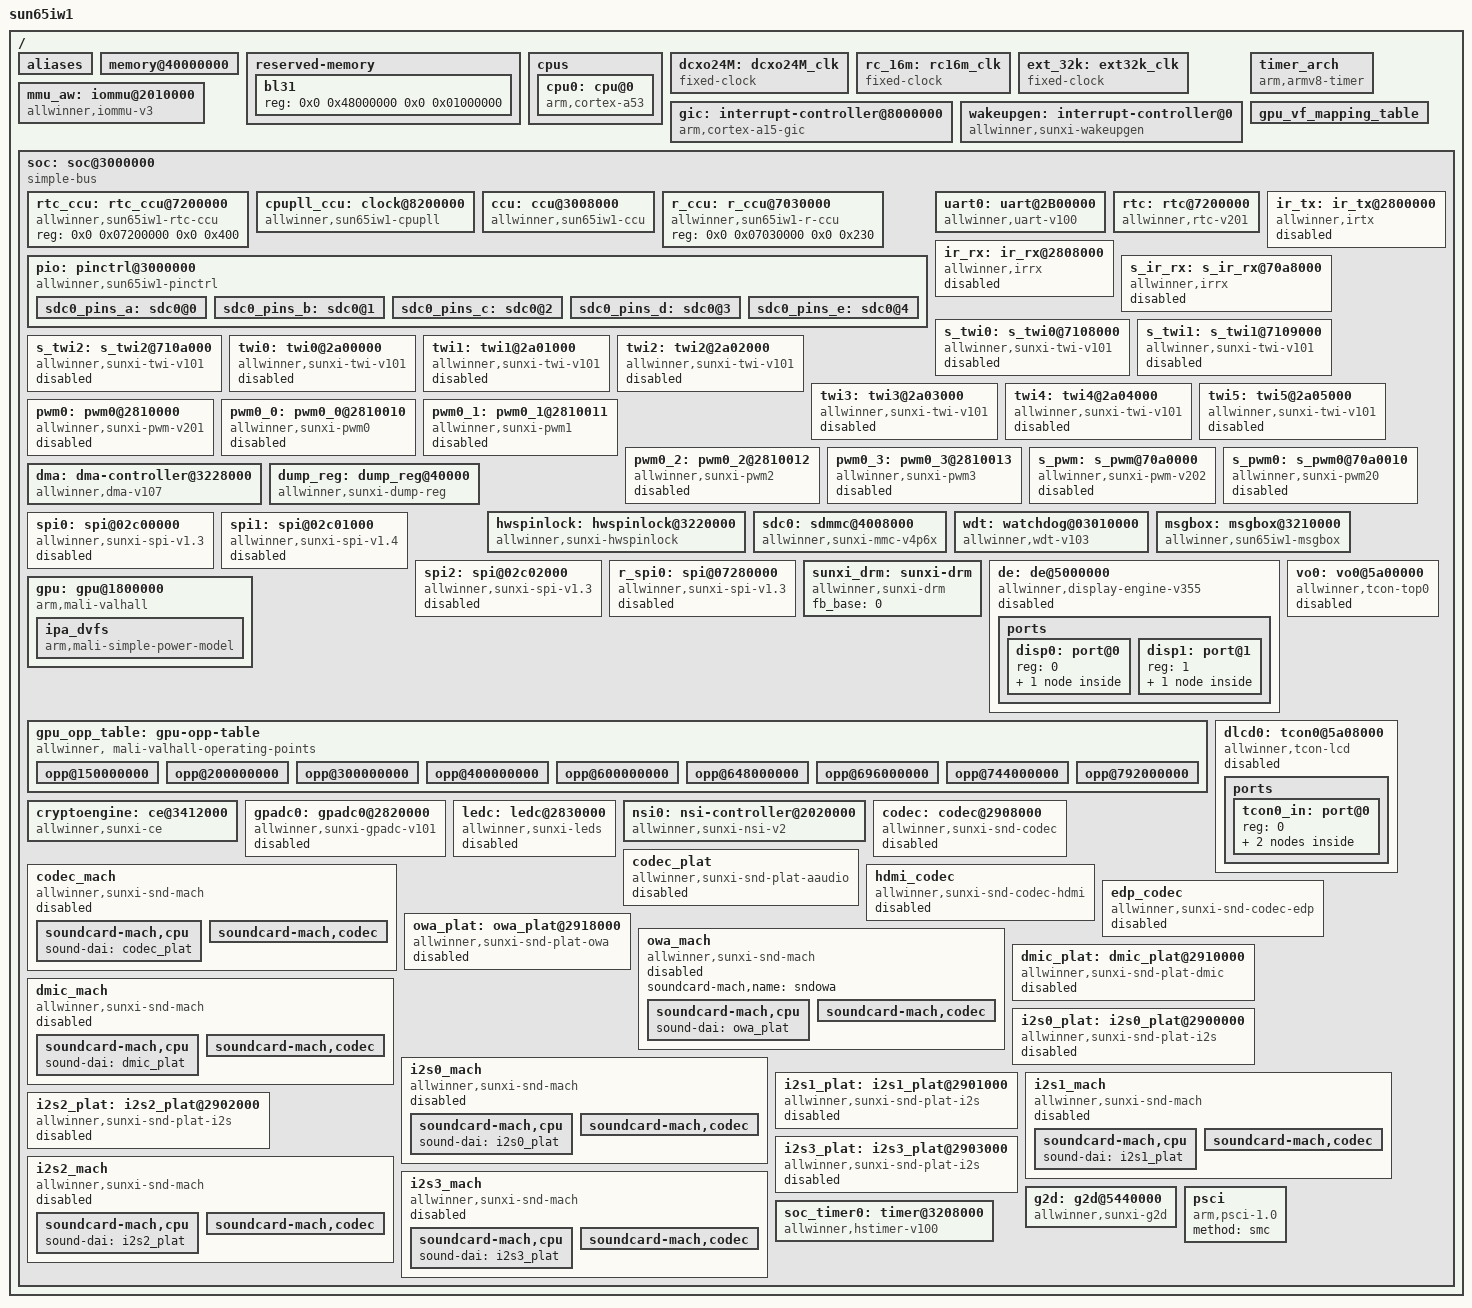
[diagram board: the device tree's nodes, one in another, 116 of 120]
// SPDX-License-Identifier: (GPL-2.0+ or MIT)
#include <dt-bindings/clock/sun65iw1-ccu.h>
#include <dt-bindings/clock/sun65iw1-rtc.h>
#include <dt-bindings/clock/sun65iw1-r-ccu.h>
#include <dt-bindings/clock/sun65iw1-displl-ccu.h>
#include <dt-bindings/gpio/gpio.h>
#include <dt-bindings/gpio/sun4i-gpio.h>
#include <dt-bindings/reset/sun65iw1-ccu.h>
#include <dt-bindings/reset/sun65iw1-r-ccu.h>
#include <dt-bindings/interrupt-controller/arm-gic.h>
#include <dt-bindings/phy/phy.h>
#include <dt-bindings/thermal/thermal.h>
#include <dt-bindings/spi/sunxi-spi.h>

/ {
	model = "sun65iw1";
	interrupt-parent = <&wakeupgen>;
	#address-cells = <2>;
	#size-cells = <2>;

	aliases {
		serial0 = &uart0;
		ir0 = &ir_rx;
		ir1 = &s_ir_rx;
		spi0 = &spi0;
		spi1 = &spi1;
		spi2 = &spi2;
		spi3 = &r_spi0;
		twi0 = &twi0;
		twi1 = &twi1;
		twi2 = &twi2;
		twi3 = &twi3;
		twi4 = &twi4;
		twi5 = &twi5;
		twi6 = &s_twi0;
		twi7 = &s_twi1;
		twi8 = &s_twi2;
	};

	/* avoid panic when memory-node err(from uboot) */
	memory@40000000 {
		device_type = "memory";
		reg = <0x00000000 0x40000000 0x00000000 0x20000000>;
	};

	reserved-memory {
		#address-cells = <2>;
		#size-cells = <2>;
		ranges;

		bl31 {
			reg = <0x0 0x48000000 0x0 0x01000000>;
		};
	};

	cpus {
		#address-cells = <2>;
		#size-cells = <0>;

		cpu0: cpu@0 {
			device_type = "cpu";
			compatible = "arm,cortex-a53";
			reg = <0x0 0x0>;
			enable-method = "psci";
		};
	};

	dcxo24M: dcxo24M_clk {
		#clock-cells = <0>;
		compatible = "fixed-clock";
		clock-frequency = <24000000>;
		clock-output-names = "dcxo24M";
	};

	rc_16m: rc16m_clk {
		#clock-cells = <0>;
		compatible = "fixed-clock";
		clock-frequency = <16000000>;
		clock-accuracy = <300000000>;
		clock-output-names = "rc-16m";
	};

	ext_32k: ext32k_clk {
		#clock-cells = <0>;
		compatible = "fixed-clock";
		clock-frequency = <32768>;
		clock-output-names = "ext-32k";
	};

	gic: interrupt-controller@8000000{
		compatible = "arm,cortex-a15-gic", "arm,cortex-a9-gic";
		#interrupt-cells = <3>;
		#address-cells = <0>;
		device_type = "gic";
		interrupt-controller;
		reg = <0x0 0x08001000 0 0x1000>, /* GIC Dist */
			<0x0 0x08002000 0 0x2000>, /* GIC CPU */
			<0x0 0x08004000 0 0x2000>, /* GIC VCPU Control */
			<0x0 0x08006000 0 0x2000>; /* GIC VCPU */
		interrupts = <GIC_PPI 9 0xf04>; /* GIC Maintenence IRQ */
		interrupt-parent = <&gic>;
	};

	wakeupgen: interrupt-controller@0 {
		compatible = "allwinner,sunxi-wakeupgen";
		interrupt-controller;
		#interrupt-cells = <3>;
		#address-cells = <0>;
		interrupt-parent = <&gic>;
	};

	timer_arch {
		compatible = "arm,armv8-timer";
		interrupts = <GIC_PPI 13 (GIC_CPU_MASK_SIMPLE(4) | IRQ_TYPE_LEVEL_LOW)>,
			     <GIC_PPI 14 (GIC_CPU_MASK_SIMPLE(4) | IRQ_TYPE_LEVEL_LOW)>,
			     <GIC_PPI 11 (GIC_CPU_MASK_SIMPLE(4) | IRQ_TYPE_LEVEL_LOW)>,
			     <GIC_PPI 10 (GIC_CPU_MASK_SIMPLE(4) | IRQ_TYPE_LEVEL_LOW)>;
		clock-frequency = <24000000>;
		interrupt-parent = <&gic>;
		arm,no-tick-in-suspend;
	};

	mmu_aw: iommu@2010000 {
		compatible = "allwinner,iommu-v3";
		reg = <0x0 0x02000000 0x0 0x1000>;
		interrupts = <GIC_SPI 91 IRQ_TYPE_LEVEL_HIGH>;
		interrupt-names = "iommu-irq";
		clocks = <&ccu CLK_APB_IOMMU>;
		clock-names = "iommu";
		/* clock-frequency = <24000000>; */
		#iommu-cells = <2>;
		version=<0x17>;
		tlb_prefetch = <0x3007f>;
		tlb_invalid_mode = <0x1>;
		ptw_invalid_mode = <0x1>;
		masters = "ISP", "CSI", "VE0", "Eink", "G2D",
			"DE", "RESERVED", "DEBUG_MODE";
		valid_masters=<7>;
	};

	gpu_vf_mapping_table: gpu_vf_mapping_table {
		table = <
			0x01 1
			0x02 2
			0x12 21
			0x04 3
			0x14 31
			0x05 4
			0x06 5
			>;
	};

	soc: soc@3000000 {
		compatible = "simple-bus";
		#address-cells = <2>;
		#size-cells = <2>;
		ranges;

		rtc_ccu: rtc_ccu@7200000 {
			compatible = "allwinner,sun65iw1-rtc-ccu";
			reg = <0x0 0x07200000 0x0 0x400>;
			#clock-cells = <1>;
			#reset-cells = <1>;
		};

		cpupll_ccu: clock@8200000 {
			compatible = "allwinner,sun65iw1-cpupll";
			reg = <0x0 0x08200000 0x0 0x050c>;
			#clock-cells = <1>;
			#reset-cells = <1>;
			pll_step = <0x9>;
			/* pll_ssc will divid pll_ssc_scale in code
			 * keep value 0 < pll_ssc < 10
			 */
			pll_ssc_scale = <0xa>;
			pll_ssc = <0x1>;
		};

		ccu: ccu@3008000 {
			compatible = "allwinner,sun65iw1-ccu";
			reg = <0x0 0x03008000 0x0 0x2000>;
			clocks = <&dcxo24M>, <&rtc_ccu CLK_OSC32K>, <&rc_16m>;
			clock-names = "hosc", "losc", "iosc";
			#clock-cells = <1>;
			#reset-cells = <1>;
		};

		r_ccu: r_ccu@7030000 {
			compatible = "allwinner,sun65iw1-r-ccu";
			reg = <0x0 0x07030000 0x0 0x230>;
			#clock-cells = <1>;
			#reset-cells = <1>;
		};

		pio: pinctrl@3000000 {
			compatible = "allwinner,sun65iw1-pinctrl";
			reg = <0x0 0x03000000 0x0 0x800>;
			interrupts = <GIC_SPI 134 IRQ_TYPE_LEVEL_HIGH>,
				     <GIC_SPI 138 IRQ_TYPE_LEVEL_HIGH>;
			clocks = <&ccu CLK_APB1>, <&dcxo24M>, <&rtc_ccu CLK_OSC32K>;
			clock-names = "apb", "hosc", "losc";
			gpio-controller;
			#gpio-cells = <3>;
			interrupt-controller;
			#interrupt-cells = <3>;

			sdc0_pins_a: sdc0@0 {
				pins = "PF0", "PF1", "PF2",
						"PF3", "PF4", "PF5";
				function = "sdc0";
				drive-strength = <40>;
				bias-pull-up;
				power-source = <3300>;
			};

			sdc0_pins_b: sdc0@1 {
				pins = "PF0", "PF1", "PF2",
						"PF3", "PF4", "PF5";
				function = "sdc0";
				drive-strength = <40>;
				bias-pull-up;
				power-source = <1800>;
			};

			sdc0_pins_c: sdc0@2 {
				pins = "PF0", "PF1", "PF2",
				"PF3", "PF4", "PF5";
				function = "gpio_in";
			};

			/* TODO: add jtag pin */
			sdc0_pins_d: sdc0@3 {
				pins = "PF2", "PF4";
				function = "uart0";
				drive-strength = <10>;
				bias-pull-up;
			};

			sdc0_pins_e: sdc0@4 {
				pins = "PF0", "PF1", "PF3",
						"PF5";
				function = "jtag";
				drive-strength = <10>;
				bias-pull-up;
			};

		};

		uart0: uart@2B00000 {
			compatible = "allwinner,uart-v100";
			reg = <0x0 0x02B00000 0x0 0x400>;
			interrupts = <GIC_SPI 2 IRQ_TYPE_LEVEL_HIGH>;
			clocks = <&ccu CLK_BUS_UART0>;
			resets = <&ccu RST_BUS_UART0>;
			uart0_port = <0>;
			uart0_type = <2>;
		};

		rtc: rtc@7200000 {
			compatible = "allwinner,rtc-v201";
			device_type = "rtc";
			wakeup-source;
			reg = <0x0 0x07200000 0x0 0x320>;
			interrupts = <GIC_SPI 232 IRQ_TYPE_LEVEL_HIGH>;
			clocks = <&r_ccu CLK_RTC>, <&rtc_ccu CLK_RTC_1K>, <&rtc_ccu CLK_RTC_SPI>;
			clock-names = "r-ahb-rtc", "rtc-1k", "rtc-spi";
			resets = <&r_ccu RST_BUS_RTC>;
			gpr_cur_pos = <6>;
			gpr_bootcount_pos = <7>;
		};

		ir_tx: ir_tx@2800000 {
			compatible = "allwinner,irtx";
			reg = <0x0 0x02800000 0x0 0x400>;
			interrupts = <GIC_SPI 30 IRQ_TYPE_LEVEL_HIGH>;
			clocks = <&ccu CLK_APB_IRTX>, <&dcxo24M>, <&ccu CLK_IRTX>;
			clock-names = "bus", "pclk", "mclk";
			resets = <&ccu RST_BUS_IRTX>;
			status = "disabled";
		};

		ir_rx: ir_rx@2808000 {
			compatible = "allwinner,irrx";
			reg = <0x0 0x02808000 0x0 0x400>;
			interrupts = <GIC_SPI 31 IRQ_TYPE_LEVEL_HIGH>;
			clocks = <&ccu CLK_APB_IRRX0>, <&dcxo24M>, <&ccu CLK_IRRX0>;
			clock-names = "bus", "pclk", "mclk";
			resets = <&ccu RST_BUS_IRRX0>;
			status = "disabled";
		};

		s_ir_rx: s_ir_rx@70a8000 {
			compatible = "allwinner,irrx";
			reg = <0x0 0x070a8000 0x0 0x400>;
			interrupts = <GIC_SPI 242 IRQ_TYPE_LEVEL_HIGH>;
			clocks = <&r_ccu CLK_BUS_R_IRRX>, <&dcxo24M>, <&r_ccu CLK_R_IRRX>;
			clock-names = "bus", "pclk", "mclk";
			resets = <&r_ccu RST_BUS_R_IRRX>;
			status = "disabled";
		};

		s_twi0: s_twi0@7108000 {
			#address-cells = <1>;
			#size-cells = <0>;
			compatible = "allwinner,sunxi-twi-v101";
			device_type = "s_twi0";
			reg = <0x0 0x07108000 0x0 0x400>;
			interrupts = <GIC_SPI 239 IRQ_TYPE_LEVEL_HIGH>;
			clocks = <&r_ccu CLK_R_TWI0>;
			clock-names = "bus";
			resets = <&r_ccu RST_BUS_R_TWI0>;
			dmas = <&dma 56>, <&dma 56>;
			dma-names = "tx", "rx";
			status = "disabled";
		};

		s_twi1: s_twi1@7109000 {
			#address-cells = <1>;
			#size-cells = <0>;
			compatible = "allwinner,sunxi-twi-v101";
			device_type = "s_twi1";
			reg = <0x0 0x07109000 0x0 0x400>;
			interrupts = <GIC_SPI 240 IRQ_TYPE_LEVEL_HIGH>;
			clocks = <&r_ccu CLK_R_TWI1>;
			clock-names = "bus";
			resets = <&r_ccu RST_BUS_R_TWI1>;
			dmas = <&dma 57>, <&dma 57>;
			dma-names = "tx", "rx";
			status = "disabled";
		};

		s_twi2: s_twi2@710a000 {
			#address-cells = <1>;
			#size-cells = <0>;
			compatible = "allwinner,sunxi-twi-v101";
			device_type = "s_twi2";
			reg = <0x0 0x0710a000 0x0 0x400>;
			interrupts = <GIC_SPI 241 IRQ_TYPE_LEVEL_HIGH>;
			clocks = <&r_ccu CLK_R_TWI2>;
			clock-names = "bus";
			resets = <&r_ccu RST_BUS_R_TWI2>;
			dmas = <&dma 58>, <&dma 58>;
			dma-names = "tx", "rx";
			status = "disabled";
		};

		twi0: twi0@2a00000 {
			#address-cells = <1>;
			#size-cells = <0>;
			compatible = "allwinner,sunxi-twi-v101";
			device_type = "twi0";
			reg = <0x0 0x02a00000 0x0 0x400>;
			interrupts = <GIC_SPI 10 IRQ_TYPE_LEVEL_HIGH>;
			clocks = <&ccu CLK_BUS_TWI0>;
			clock-names = "bus";
			resets = <&ccu RST_BUS_TWI0>;
			dmas = <&dma 14>, <&dma 14>;
			dma-names = "tx", "rx";
			status = "disabled";
		};

		twi1: twi1@2a01000 {
			#address-cells = <1>;
			#size-cells = <0>;
			compatible = "allwinner,sunxi-twi-v101";
			device_type = "twi1";
			reg = <0x0 0x02a01000 0x0 0x400>;
			interrupts = <GIC_SPI 11 IRQ_TYPE_LEVEL_HIGH>;
			clocks = <&ccu CLK_BUS_TWI1>;
			clock-names = "bus";
			resets = <&ccu RST_BUS_TWI1>;
			dmas = <&dma 15>, <&dma 15>;
			dma-names = "tx", "rx";
			status = "disabled";
		};

		twi2: twi2@2a02000 {
			#address-cells = <1>;
			#size-cells = <0>;
			compatible = "allwinner,sunxi-twi-v101";
			device_type = "twi2";
			reg = <0x0 0x02a02000 0x0 0x400>;
			interrupts = <GIC_SPI 12 IRQ_TYPE_LEVEL_HIGH>;
			clocks = <&ccu CLK_BUS_TWI2>;
			clock-names = "bus";
			resets = <&ccu RST_BUS_TWI2>;
			dmas = <&dma 16>, <&dma 16>;
			dma-names = "tx", "rx";
			status = "disabled";
		};

		twi3: twi3@2a03000 {
			#address-cells = <1>;
			#size-cells = <0>;
			compatible = "allwinner,sunxi-twi-v101";
			device_type = "twi3";
			reg = <0x0 0x02a03000 0x0 0x400>;
			interrupts = <GIC_SPI 13 IRQ_TYPE_LEVEL_HIGH>;
			clocks = <&ccu CLK_BUS_TWI3>;
			clock-names = "bus";
			resets = <&ccu RST_BUS_TWI3>;
			dmas = <&dma 17>, <&dma 17>;
			dma-names = "tx", "rx";
			status = "disabled";
		};

		twi4: twi4@2a04000 {
			#address-cells = <1>;
			#size-cells = <0>;
			compatible = "allwinner,sunxi-twi-v101";
			device_type = "twi4";
			reg = <0x0 0x02a04000 0x0 0x400>;
			interrupts = <GIC_SPI 14 IRQ_TYPE_LEVEL_HIGH>;
			clocks = <&ccu CLK_BUS_TWI4>;
			clock-names = "bus";
			resets = <&ccu RST_BUS_TWI4>;
			dmas = <&dma 18>, <&dma 18>;
			dma-names = "tx", "rx";
			status = "disabled";
		};

		twi5: twi5@2a05000{
			#address-cells = <1>;
			#size-cells = <0>;
			compatible = "allwinner,sunxi-twi-v101";
			device_type = "twi5";
			reg = <0x0 0x02a05000 0x0 0x400>;
			interrupts = <GIC_SPI 15 IRQ_TYPE_LEVEL_HIGH>;
			clocks = <&ccu CLK_BUS_TWI5>;
			clock-names = "bus";
			resets = <&ccu RST_BUS_TWI5>;
			dmas = <&dma 19>, <&dma 19>;
			dma-names = "tx", "rx";
			status = "disabled";
		};

		pwm0: pwm0@2810000 {
			#pwm-cells = <0x3>;
			compatible = "allwinner,sunxi-pwm-v201";
			reg = <0x0 0x02810000 0x0 0x400>;
			clocks = <&ccu CLK_APB_PWM0>;
			interrupts = <GIC_SPI 26 IRQ_TYPE_LEVEL_HIGH>;
			resets = <&ccu RST_BUS_PWM0>;
			pwm-number = <4>;
			pwm-base = <0x0>;
			sunxi-pwms = <&pwm0_0>, <&pwm0_1>, <&pwm0_2>, <&pwm0_3>;
			status = "disabled";
		};

		pwm0_0: pwm0_0@2810010 {
			compatible = "allwinner,sunxi-pwm0";
			pinctrl-names = "active", "sleep";
			reg = <0x0 0x02810010 0x0 0x4>;
			reg_base = <0x02810000>;
			status = "disabled";
		};

		pwm0_1: pwm0_1@2810011 {
			compatible = "allwinner,sunxi-pwm1";
			pinctrl-names = "active", "sleep";
			reg = <0x0 0x02810011 0x0 0x4>;
			reg_base = <0x02810000>;
			status = "disabled";
		};

		pwm0_2: pwm0_2@2810012 {
			compatible = "allwinner,sunxi-pwm2";
			pinctrl-names = "active", "sleep";
			reg = <0x0 0x02810012 0x0 0x4>;
			reg_base = <0x02810000>;
			status = "disabled";
		};

		pwm0_3: pwm0_3@2810013 {
			compatible = "allwinner,sunxi-pwm3";
			pinctrl-names = "active", "sleep";
			reg = <0x0 0x02810013 0x0 0x4>;
			reg_base = <0x02810000>;
			status = "disabled";
		};

		s_pwm: s_pwm@70a0000 {
			#pwm-cells = <0x3>;
			compatible = "allwinner,sunxi-pwm-v202";
			reg = <0x0 0x070a0000 0x0 0x400>;
			clocks = <&r_ccu CLK_R_PWM>,<&r_ccu CLK_BUS_R_PWM>;
			interrupts = <GIC_SPI 243 IRQ_TYPE_LEVEL_HIGH>;
			clock-names = "clk_pwm","clk_bus_pwm";
			resets = <&r_ccu RST_BUS_R_PWM>;
			pwm-number = <1>;
			pwm-base = <0x4>;
			sunxi-pwms = <&s_pwm0>;
			status = "disabled";
		};

		s_pwm0: s_pwm0@70a0010 {
			compatible = "allwinner,sunxi-pwm20";
			pinctrl-names = "active", "sleep";
			reg = <0x0 0x070a0010 0x0 0x4>;
			reg_base = <0x070a0000>;
			status = "disabled";
		};

		dma: dma-controller@3228000 {
			compatible = "allwinner,dma-v107";
			reg = <0x0 0x3228000 0x0 0x2000>;
			interrupts = <GIC_SPI 100 IRQ_TYPE_LEVEL_HIGH>;
			clocks = <&ccu CLK_AHB_DMA>, <&ccu CLK_MBUS_DMAC0_GATE>;
			clock-names = "bus", "mbus";
			dma-channels = <8>;
			dma-requests = <64>;
			resets = <&ccu RST_BUS_DMAC0>;
			#dma-cells = <1>;
		};

		dump_reg:dump_reg@40000 {
			compatible = "allwinner,sunxi-dump-reg";
			reg = <0x0 0x00040000 0x0 0x0004>;
			ddr-range = <8>;
		};

		hwspinlock: hwspinlock@3220000 {
			compatible = "allwinner,sunxi-hwspinlock";
			reg = <0x0 0x3220000 0x0 0x1000>;
			#hwlock-cells = <1>;
			clocks = <&ccu CLK_AHB_SPINLOCK>;
			clock-names = "clk_hwspinlock_bus";
			resets = <&ccu RST_BUS_SPINLOCK>;
			reset-names = "rst";
			num-locks = <32>;
			status = "okay";
		};

		sdc0: sdmmc@4008000 {
			compatible = "allwinner,sunxi-mmc-v4p6x";
			device_type = "sdc0";
			reg = <0x0 0x04008000 0x0 0x1000>;
			interrupts = <GIC_SPI 80 IRQ_TYPE_LEVEL_HIGH>;
			clocks = <&dcxo24M>,
				<&ccu CLK_PLL_PERI1_400M>,
				<&ccu CLK_PLL_PERI1_300M>,
				<&ccu CLK_SMHC0>,
				<&ccu CLK_BUS_SMHC0>;
			clock-names = "osc24m","pll_periph","pll_periph_2","mmc","ahb";
			resets = <&ccu RST_BUS_SMHC0>;
			reset-names = "rst";
			pinctrl-names = "default","mmc_1v8","sleep","uart_jtag";
			pinctrl-0 = <&sdc0_pins_a>;
			pinctrl-1 = <&sdc0_pins_b>;
			pinctrl-2 = <&sdc0_pins_c>;
			pinctrl-3 = <&sdc0_pins_d &sdc0_pins_e>;
			max-frequency = <50000000>;
			bus-width = <4>;
			req-page-count = <2>;
			/*non-removable;*/
			/*broken-cd;*/
			/*cd-inverted*/
			/*cd-gpios = <&pio PF 6 GPIO_ACTIVE_LOW>;*/
			/* vmmc-supply = <&reg_3p3v>;*/
			/* vqmc-supply = <&reg_3p3v>;*/
			/* vdmc-supply = <&reg_3p3v>;*/
			/*vmmc = "vcc-card";*/
			/*vqmc = "";*/
			/*vdmc = "";*/
			cap-sd-highspeed;
			cap-wait-while-busy;
			/*sd-uhs-sdr50;*/
			/*sd-uhs-ddr50;*/
			/*cap-sdio-irq;*/
			/*keep-power-in-suspend;*/
			/*ignore-pm-notify;*/
			/*sunxi-power-save-mode;*/
			/*sunxi-dly-400k = <1 0 0 0>; */
			/*sunxi-dly-26M  = <1 0 0 0>;*/
			/*sunxi-dly-52M  = <1 0 0 0>;*/
			/*sunxi-dly-52M-ddr4  = <1 0 0 0>;*/
			/*sunxi-dly-52M-ddr8  = <1 0 0 0>;*/
			/*sunxi-dly-104M  = <1 0 0 0>;*/
			/*sunxi-dly-208M  = <1 0 0 0>;*/
			/*sunxi-dly-104M-ddr  = <1 0 0 0>;*/
			/*sunxi-dly-208M-ddr  = <1 0 0 0>;*/
			ctl-spec-caps = <0x408>;
			status = "okay";
		};

		wdt: watchdog@03010000 {
			compatible = "allwinner,wdt-v103";
			reg = <0x0 0x03010000 0x0 0x20>;
			interrupts = <GIC_SPI 106 IRQ_TYPE_LEVEL_HIGH>;  /* In GIC Spec */
		};

		/*
		 * channel0~3  : cpux -> e902
		 */
		msgbox: msgbox@3210000 {
			compatible = "allwinner,sun65iw1-msgbox";
			#mbox-cells = <1>;
			reg = <0x0 0x03210000 0x0 0x1000>,
			      <0x0 0x03211000 0x0 0x1000>;
			interrupts = <GIC_SPI 0 IRQ_TYPE_LEVEL_HIGH>,
					<GIC_SPI 1 IRQ_TYPE_LEVEL_HIGH>;
			clocks = <&ccu CLK_AHB_MSGBOX_CPUX>;
			clock-names = "msgbox";
			resets = <&ccu RST_BUS_MSGBOX_CPUX>;
			reset-names = "rst";
			local_id = <0>;
			status = "okay";
		};

		spi0: spi@02c00000 {
			#address-cells = <1>;
			#size-cells = <0>;
			compatible = "allwinner,sunxi-spi-v1.3";
			reg = <0x0 0x02c00000 0x0 0x1000>;
			interrupts = <GIC_SPI 18 IRQ_TYPE_LEVEL_HIGH>;
			clocks = <&ccu CLK_PLL_PERI0_300M>, <&ccu CLK_SPI0>, <&ccu CLK_AHB_SPI0>;
			clock-names = "pll", "mod", "bus";
			resets = <&ccu RST_BUS_SPI0>;
			dmas = <&dma 22>, <&dma 22>;
			dma-names = "tx", "rx";
			clock-frequency = <100000000>;
			sunxi,spi-num-cs = <2>;
			status = "disabled";
		};

		spi1: spi@02c01000 {
			#address-cells = <1>;
			#size-cells = <0>;
			compatible = "allwinner,sunxi-spi-v1.4";
			reg = <0x0 0x02c01000 0x0 0x1000>;
			interrupts = <GIC_SPI 19 IRQ_TYPE_LEVEL_HIGH>;
			clocks = <&ccu CLK_PLL_PERI0_300M>, <&ccu CLK_SPI1>, <&ccu CLK_AHB_SPI1>;
			clock-names = "pll", "mod", "bus";
			resets = <&ccu RST_BUS_SPI1>;
			dmas = <&dma 23>, <&dma 23>;
			dma-names = "tx", "rx";
			clock-frequency = <100000000>;
			sunxi,spi-num-cs = <1>;
			status = "disabled";
		};

		spi2: spi@02c02000 {
			#address-cells = <1>;
			#size-cells = <0>;
			compatible = "allwinner,sunxi-spi-v1.3";
			reg = <0x0 0x02c02000 0x0 0x1000>;
			interrupts = <GIC_SPI 20 IRQ_TYPE_LEVEL_HIGH>;
			clocks = <&ccu CLK_PLL_PERI0_300M>, <&ccu CLK_SPI2>, <&ccu CLK_AHB_SPI2>;
			clock-names = "pll", "mod", "bus";
			resets = <&ccu RST_BUS_SPI2>;
			dmas = <&dma 24>, <&dma 24>;
			dma-names = "tx", "rx";
			clock-frequency = <100000000>;
			sunxi,spi-num-cs = <1>;
			status = "disabled";
		};

		r_spi0: spi@07280000 {
			#address-cells = <1>;
			#size-cells = <0>;
			compatible = "allwinner,sunxi-spi-v1.3";
			reg = <0x0 0x07280000 0x0 0x1000>;
			interrupts = <GIC_SPI 246 IRQ_TYPE_LEVEL_HIGH>;
			clocks = <&ccu CLK_PLL_PERI0_300M>, <&r_ccu CLK_R_SPI>, <&r_ccu CLK_BUS_R_SPI>;
			clock-names = "pll", "mod", "bus";
			resets = <&r_ccu RST_BUS_R_SPI>;
			dmas = <&dma 62>, <&dma 62>;
			dma-names = "tx", "rx";
			clock-frequency = <100000000>;
			sunxi,spi-num-cs = <1>;
			status = "disabled";
		};

		sunxi_drm: sunxi-drm {
			compatible = "allwinner,sunxi-drm";
			fb_base = <0>;
			status = "okay";
		};

		de: de@5000000 {
			compatible = "allwinner,display-engine-v355";
//			iommus = <&mmu_aw 5 1>;
			reg = <0x0 0x5000000 0x0 0x400000>;
			interrupts = <GIC_SPI 146 IRQ_TYPE_LEVEL_HIGH>;
			clocks = <&ccu CLK_DE>,
				 <&ccu CLK_AHB_DE0>,
				 <&ccu CLK_MBUS_DE_SYS_GATE>;
			clock-names = "clk_de",
				      "clk_ahb_de",
				      "clk_bus_de";
			resets = <&ccu RST_BUS_DE0>,
				<&ccu RST_BUS_DE_SY>;
			reset-names = "rst_bus_de",
				      "rst_bus_de_sys";
			sys = <&vo0>;
			status = "disabled";
			ports {
				#address-cells = <1>;
				#size-cells = <0>;
				disp0: port@0 {
					reg = <0>;
					#address-cells = <1>;
					#size-cells = <0>;
					disp0_out_tcon0: endpoint@0 {
						reg = <0>;
						remote-endpoint = <&tcon0_in_disp0>;
					};
				};
				disp1: port@1 {
					reg = <1>;
					#address-cells = <1>;
					#size-cells = <0>;
					disp1_out_tcon0: endpoint@0 {
						reg = <0>;
						remote-endpoint = <&tcon0_in_disp1>;
					};
				};
			};
		};

		gpu:gpu@1800000 {
			device_type = "gpu";
			compatible = "arm,mali-valhall";
			reg = <0x0 0x01800000 0x0 0x10000>;
			interrupts = <GIC_SPI 117 IRQ_TYPE_LEVEL_HIGH>,
				     <GIC_SPI 118 IRQ_TYPE_LEVEL_HIGH>,
				     <GIC_SPI 119 IRQ_TYPE_LEVEL_HIGH>;
			interrupt-names = "JOB", "MMU", "GPU";
			//clocks = <&ccu CLK_GPU>, <&ccu CLK_BUS_GPU>, <&ccu CLK_PLL_GPU>;
			clock-names = "clk_mali", "clk_bus", "clk_parent";
			resets = <&ccu RST_BUS_GPU>;
			operating-points-v2 = <&gpu_opp_table>;
			#cooling-cells = <2>;
			ipa_dvfs:ipa_dvfs {
				compatible = "arm,mali-simple-power-model";
				static-coefficient = <636>;
				dynamic-coefficient = <1434>;
				/* ts0 -> ts3 */
				ts = <0xcc77c0 217000 0xffffd508 200>;
				thermal-zone = "gpu_thermal_zone";
				/*ss-coefficient = <36>;*/
				/*ff-coefficient = <291>;*/
			};
			/*power-domains = <&pd1 A523_PCK_GPU>;*/
		};

		gpu_opp_table: gpu-opp-table {
			compatible = "allwinner, mali-valhall-operating-points";
			opp@150000000 {
				opp-hz = /bits/ 64 <150000000>;
				opp-microvolt = <900000>;
			};

			opp@200000000 {
				opp-hz = /bits/ 64 <200000000>;
				opp-microvolt = <900000>;
			};

			opp@300000000 {
				opp-hz = /bits/ 64 <300000000>;
				opp-microvolt = <900000>;
			};

			opp@400000000 {
				opp-hz = /bits/ 64 <400000000>;
				opp-microvolt = <900000>;
			};

			opp@600000000 {
				opp-hz = /bits/ 64 <600000000>;
				opp-microvolt = <900000>;
			};

			opp@648000000 {
				opp-hz = /bits/ 64 <648000000>;
				opp-microvolt = <0>;
				opp-microvolt-vf0900 = <900000>;
			};

			opp@696000000 {
				opp-hz = /bits/ 64 <696000000>;
				opp-microvolt = <0>;
				opp-microvolt-vf1920 = <900000>;
				opp-microvolt-vf2920 = <900000>;
				opp-microvolt-vf3920 = <900000>;
				opp-microvolt-vf21920 = <900000>;
				opp-microvolt-vf31920 = <900000>;
				opp-microvolt-vf5920 = <900000>;
			};

			opp@744000000 {
				opp-hz = /bits/ 64 <744000000>;
				opp-microvolt = <0>;
				opp-microvolt-vf4920 = <900000>;
				/* Not use: only for performance test
				   opp-microvolt-vf2920 = <900000>;
				   opp-microvolt-vf3920 = <900000>;
				   opp-microvolt-vf21920 = <900000>;
				   opp-microvolt-vf31920 = <900000>;
				*/
			};

			/* Not use: only for performance test */
			opp@792000000 {
				opp-hz = /bits/ 64 <792000000>;
				opp-microvolt = <0>;
				/* opp-microvolt-vf2950 = <900000>;
				   opp-microvolt-vf3950 = <900000>;
				   opp-microvolt-vf21950 = <900000>;
				   opp-microvolt-vf31950 = <900000>;
				*/
			};
		};

		vo0: vo0@5a00000 {
			compatible = "allwinner,tcon-top0";
			reg = <0x0 0x05a00000 0x0 0xfff>;
			clocks = <&ccu CLK_AHB_VO0>,
				 <&ccu CLK_AHB_VIDEO_OUT0_GATE>,
				 <&ccu CLK_MBUS_VIDEO_OUT0_GATE>;
			clock-names = "clk_ahb",
				      "clk_ahb_gate",
				      "clk_bus_dpss_top";
			resets = <&ccu RST_BUS_VIDEO_OUT0>,
				 <&ccu RST_BUS_VO0_REG>;
			reset-names = "rst_bus_dpss_top",
				       "rst_bus_reg";
			status = "disabled";
		};

		dlcd0: tcon0@5a08000 {
			compatible = "allwinner,tcon-lcd";
			reg = <0x0 0x05a08000 0x0 0x1000>;
			interrupts = <GIC_SPI 154 IRQ_TYPE_LEVEL_HIGH>;
			clocks = <&ccu CLK_AHB_TCON_LCD0>;
			clock-names = "clk_ahb_tcon";
			resets = <&ccu RST_BUS_TCON_LCD0>;
			reset-names = "rst_bus_tcon";
			top = <&vo0>;
			status = "disabled";
			ports {
				#address-cells = <1>;
				#size-cells = <0>;
				tcon0_in: port@0 {
					#address-cells = <1>;
					#size-cells = <0>;
					reg = <0>;
					tcon0_in_disp0: endpoint@0 {
						reg = <0>;
						remote-endpoint = <&disp0_out_tcon0>;
					};
					tcon0_in_disp1: endpoint@1 {
						reg = <1>;
						remote-endpoint = <&disp1_out_tcon0>;
					};
				};
			};
		};

		cryptoengine: ce@3412000 {
			compatible = "allwinner,sunxi-ce";
			device_name = "ce";
			reg = <0x0 0x03412000 0x0 0x800>, /* non-secure space */
				<0x0 0x03412800 0x0 0x800>; /* secure space */
			interrupts = <GIC_SPI 96 IRQ_TYPE_EDGE_RISING>, /*non-secure*/
				<GIC_SPI 97 IRQ_TYPE_EDGE_RISING>; /* secure*/
			clock-frequency = <400000000>; /* 400MHz */
			clocks = <&ccu CLK_CE_SYS_AHB>, <&ccu CLK_CE_SYS_IP_AHB>, <&ccu CLK_CE_SYS_AXI_GATE>,
				 <&ccu CLK_PLL_PERI0_400M>, <&ccu CLK_CE_SYS>;
			clock-names = "bus_ce", "ce_clk", "mbus_ce", "clk_src", "ce_sys_clk";
			resets = <&ccu RST_BUS_CE_SYS_AHB>, <&ccu RST_BUS_CE_SY>;
			reset-names = "rst_bus_ce", "rst_ce_clk";
			status = "okay";
		};

		gpadc0: gpadc0@2820000 {
			compatible = "allwinner,sunxi-gpadc-v101";
			reg = <0x0 0x02820000 0x0 0x400>;
			interrupts = <GIC_SPI 36 IRQ_TYPE_LEVEL_HIGH>;
			clocks = <&ccu CLK_APB_GPADC0>, <&ccu CLK_GPADC0>;
			clock-names = "bus", "hosc";
			resets = <&ccu RST_BUS_GPADC0>;
			status = "disabled";
		};

		ledc: ledc@2830000 {
			#address-cells = <1>;
			#size-cells = <0>;
			compatible = "allwinner,sunxi-leds";
			reg = <0x0 0x02830000 0x0 0x400>;
			interrupts = <GIC_SPI 35 IRQ_TYPE_LEVEL_HIGH>;
			clocks = <&ccu CLK_LEDC>, <&ccu CLK_APB_LEDC>;
			clock-names = "clk_ledc", "clk_cpuapb";
			resets = <&ccu RST_BUS_LEDC>;
			reset-names = "ledc_reset";
			dmas = <&dma 12>;
			dma-names = "tx";
			status = "disabled";
		};

		nsi0: nsi-controller@2020000 {
			compatible = "allwinner,sunxi-nsi-v2";
			interrupts = <GIC_SPI 90 IRQ_TYPE_LEVEL_HIGH>;
			reg = <0x0 0x02400000 0x0 0x10000>;
			clocks = <&ccu CLK_PLL_PERI0_600M>, <&ccu CLK_MBUS>,
				<&ccu CLK_NSI>, <&ccu CLK_PLL_VIDEO0_3X>,
				<&ccu CLK_AHB>;
			clock-names = "pll", "bus", "nsi", "nsi-p","ahb";
			resets = <&ccu RST_BUS_NSI>, <&ccu RST_BUS_NSI_CFG>;
			reset-names = "bus_nsi", "bus_nsi_cfg";
			clock-frequency = <600000000>, <700000000>;
			#nsi-cells = <1>;
			clk_path_type = <1>;
			topology_type = <2>;
			channel_type = <1>;
			master_clks = <0 1>, <1 1>, <2 1>, <3 1>, <4 2>, <5 1>, <6 1>, <7 1>,
					<8 1>, <9 2>, <10 1>, <11 1>, <12 2>, <13 4>, <14 4>, <15 4>,
					<16 4>, <17 4>, <18 4>, <19 0>;
		};

		/* audio dirver module -> audio codec */
		codec:codec@2908000 {
			#sound-dai-cells = <0>;
			compatible	= "allwinner,sunxi-snd-codec";
			reg		= <0x0 0x02908000 0x0 0x348>;
			resets		= <&ccu RST_BUS_ADDA>;
			clocks		= <&ccu CLK_APB_ADDA>,
					  <&ccu CLK_ADDA_ADC>,
					  <&ccu CLK_ADDA_DAC>;
			clock-names	= "clk_apb_adda",
					  "clk_adda_adc",
					  "clk_adda_dac";
			interrupts	= <GIC_SPI 58 IRQ_TYPE_LEVEL_HIGH>;
			status = "disabled";
		};

		codec_plat:codec_plat {
			#sound-dai-cells = <0>;
			compatible	= "allwinner,sunxi-snd-plat-aaudio";
			dac-txdata	= <0x02908020>;
			adc-txdata	= <0x02908040>;
			dmas		= <&dma 7>, <&dma 7>;
			dma-names	= "tx", "rx";
			playback-cma	= <128>;
			capture-cma	= <128>;
			tx-fifo-size	= <128>;
			rx-fifo-size	= <128>;
			status = "disabled";
		};

		codec_mach:codec_mach {
			compatible = "allwinner,sunxi-snd-mach";
			soundcard-mach,name		= "audiocodec";
			soundcard-mach,pin-switches;
			soundcard-mach,routing;
			soundcard-mach,jack-support = <1>;
			status = "disabled";
			soundcard-mach,cpu {
				sound-dai = <&codec_plat>;
			};
			soundcard-mach,codec {
				sound-dai = <&codec>;
				soundcard-mach,pll-fs	= <1>;
			};
		};

		/* audio dirver module -> hdmi */
		hdmi_codec:hdmi_codec {
			#sound-dai-cells = <0>;
			compatible	= "allwinner,sunxi-snd-codec-hdmi";
			status = "disabled";
		};

		/* audio dirver module -> edp */
		edp_codec:edp_codec {
			#sound-dai-cells = <0>;
			compatible	= "allwinner,sunxi-snd-codec-edp";
			status = "disabled";
		};

		/* audio dirver module -> owa */
		owa_plat:owa_plat@2918000 {
			#sound-dai-cells = <0>;
			compatible	= "allwinner,sunxi-snd-plat-owa";
			reg		= <0x0 0x02918000 0x0 0x5C>;
			resets		= <&ccu RST_BUS_OWA0>;
			clocks		= <&ccu CLK_APB_OWA0>,
					  <&ccu CLK_OWA0_TX>,
					  <&ccu CLK_OWA0_RX>;
			clock-names	= "clk_owa0_tx",
					  "clk_owa0_rx";
			dmas		= <&dma 2>, <&dma 2>;
			dma-names	= "tx", "rx";
			playback-cma	= <128>;
			capture-cma	= <128>;
			tx-fifo-size	= <128>;
			rx-fifo-size	= <128>;
			interrupts	= <GIC_SPI 56 IRQ_TYPE_LEVEL_HIGH>;
			status = "disabled";
		};

		owa_mach:owa_mach {
			compatible = "allwinner,sunxi-snd-mach";
			soundcard-mach,name = "sndowa";
			status = "disabled";
			soundcard-mach,cpu {
				sound-dai = <&owa_plat>;
			};
			soundcard-mach,codec {
			};
		};

		/* audio dirver module -> dmic */
		dmic_plat:dmic_plat@2910000 {
			#sound-dai-cells = <0>;
			compatible	= "allwinner,sunxi-snd-plat-dmic";
			reg		= <0x0 0x02910000 0x0 0x50>;
			resets		= <&ccu RST_BUS_DMIC>;
			clocks		= <&ccu CLK_DMIC>;
			clock-names	= "clk_dmic";
			dmas		= <&dma 8>;
			dma-names	= "rx";
			capture-cma	= <128>;
			rx-fifo-size	= <128>;
			status = "disabled";
		};

		dmic_mach:dmic_mach{
			compatible = "allwinner,sunxi-snd-mach";
			soundcard-mach,name		= "snddmic";
			soundcard-mach,capture-only;
			status = "disabled";
			soundcard-mach,cpu {
				sound-dai = <&dmic_plat>;
			};
			soundcard-mach,codec {
			};
		};

		/* audio dirver module -> I2S/PCM */
		i2s0_plat:i2s0_plat@2900000 {
			#sound-dai-cells = <0>;
			compatible = "allwinner,sunxi-snd-plat-i2s";
			reg		= <0x0 0x02900000 0x0 0x7C>;
			resets		= <&ccu RST_BUS_I2S0>;
			clocks		= <&ccu CLK_APB_I2S0>,
					  <&ccu CLK_I2S0>;
			clock-names	= "clk_apb_i2s0",
					  "clk_i2s0";
			dmas		= <&dma 3>, <&dma 3>;
			dma-names	= "tx", "rx";
			playback-cma	= <128>;
			capture-cma	= <128>;
			tx-fifo-size	= <128>;
			rx-fifo-size	= <128>;
			status = "disabled";
		};

		i2s0_mach:i2s0_mach{
			compatible = "allwinner,sunxi-snd-mach";
			soundcard-mach,name		= "sndi2s0";
			soundcard-mach,format		= "i2s";
			soundcard-mach,slot-num		= <2>;
			soundcard-mach,slot-width	= <32>;
			status = "disabled";
			soundcard-mach,cpu {
				sound-dai = <&i2s0_plat>;
			};
			soundcard-mach,codec {
			};
		};

		i2s1_plat:i2s1_plat@2901000 {
			#sound-dai-cells = <0>;
			compatible = "allwinner,sunxi-snd-plat-i2s";
			reg		= <0x0 0x02901000 0x0 0x7C>;
			resets		= <&ccu RST_BUS_I2S1>;
			clocks		= <&ccu CLK_APB_I2S1>,
					  <&ccu CLK_I2S1>;
			clock-names	= "clk_apb_i2s1",
					  "clk_i2s1";
			dmas		= <&dma 4>, <&dma 4>;
			dma-names	= "tx", "rx";
			playback-cma	= <128>;
			capture-cma	= <128>;
			tx-fifo-size	= <128>;
			rx-fifo-size	= <128>;
			status = "disabled";
		};

		i2s1_mach:i2s1_mach{
			compatible = "allwinner,sunxi-snd-mach";
			soundcard-mach,name		= "sndi2s1";
			soundcard-mach,format		= "i2s";
			soundcard-mach,slot-num		= <2>;
			soundcard-mach,slot-width	= <32>;
			status = "disabled";
			soundcard-mach,cpu {
				sound-dai = <&i2s1_plat>;
			};
			soundcard-mach,codec {
			};
		};

		i2s2_plat:i2s2_plat@2902000 {
			#sound-dai-cells = <0>;
			compatible = "allwinner,sunxi-snd-plat-i2s";
			reg		= <0x0 0x02902000 0x0 0x7C>;
			resets		= <&ccu RST_BUS_I2S2>;
			clocks		= <&ccu CLK_APB_I2S2>,
					  <&ccu CLK_I2S2>;
			clock-names	= "clk_apb_i2s2",
					  "clk_i2s2";
			dmas		= <&dma 5>, <&dma 5>;
			dma-names	= "tx", "rx";
			playback-cma	= <128>;
			capture-cma	= <128>;
			tx-fifo-size	= <128>;
			rx-fifo-size	= <128>;
			status = "disabled";
		};

		i2s2_mach:i2s2_mach{
			compatible = "allwinner,sunxi-snd-mach";
			/* card name. hdmi: "sndhdmi"; edp: "sndedp" */
			soundcard-mach,name		= "sndhdmi";
			soundcard-mach,format		= "i2s";
			soundcard-mach,slot-num		= <2>;
			soundcard-mach,slot-width	= <32>;
			status = "disabled";
			soundcard-mach,cpu {
				sound-dai = <&i2s2_plat>;
			};
			soundcard-mach,codec {
			};
		};

		i2s3_plat:i2s3_plat@2903000 {
			#sound-dai-cells = <0>;
			compatible = "allwinner,sunxi-snd-plat-i2s";
			reg		= <0x0 0x02903000 0x0 0x7C>;
			resets		= <&ccu RST_BUS_I2S3>;
			clocks		= <&ccu CLK_APB_I2S3>,
					  <&ccu CLK_I2S3>;
			clock-names	= "clk_apb_i2s3",
					  "clk_i2s3";
			dmas		= <&dma 6>, <&dma 6>;
			dma-names	= "tx", "rx";
			playback-cma	= <128>;
			capture-cma	= <128>;
			tx-fifo-size	= <128>;
			rx-fifo-size	= <128>;
			status = "disabled";
		};

		i2s3_mach:i2s3_mach{
			compatible = "allwinner,sunxi-snd-mach";
			soundcard-mach,name		= "sndi2s3";
			soundcard-mach,format		= "i2s";
			soundcard-mach,slot-num		= <2>;
			soundcard-mach,slot-width	= <32>;
			status = "disabled";
			soundcard-mach,cpu {
				sound-dai = <&i2s3_plat>;
			};
			soundcard-mach,codec {
			};
		};

		g2d: g2d@5440000 {
			compatible = "allwinner,sunxi-g2d";
			reg = <0x0 0x05440000 0x0 0x30000>;
			interrupts = <GIC_SPI 148 IRQ_TYPE_LEVEL_HIGH>;
			clocks = <&ccu CLK_AHB_G2D>, <&ccu CLK_G2D>;
			clock-names = "ahb_g2d", "g2d";
			resets = <&ccu RST_BUS_G2D>;
			iommus = <&mmu_aw 4 1>;
			assigned-clocks = <&ccu CLK_G2D>;
			assigned-clock-rates = <300000000>;
		};

		psci {
			compatible = "arm,psci-1.0";
			method = "smc";
		};

		soc_timer0: timer@3208000{
			compatible = "allwinner,hstimer-v100";
			device_type = "soc_timer";
			reg = <0x0 0x03208000 0x0 0x400>;
			interrupt-parent = <&gic>;
			interrupts = <GIC_SPI 112 IRQ_TYPE_LEVEL_HIGH>;
			clock-names = "parent", "bus", "timer0-mod", "timer1-mod";
			clocks = <&dcxo24M>, <&ccu CLK_AHB_TIMER>, <&ccu CLK_TIMER0>, <&ccu CLK_TIMER1>;
			resets = <&ccu RST_BUS_TIME>;
		};
	};
};
